# STM32L562 register map
File version: 1.1
Registers are 32-bit, read-write, reset 0x0 unless marked. A register's access mark holds for its fields unless they carry their own. Offsets are from the block's base; [hi:lo] are bit positions; {n}, {i} and the like mark numbered series; 'fields as' and 'values as' point back to an identical list.

## NVIC — Nested Vectored Interrupt Controller
Base 0xE000E100
{0x0+4i} ISER{i} (i=0..2) — Interrupt Set-Enable Register
  [31:0] SETENA
0x0C ISER3 — Interrupt Set-Enable Register
{0x80+4i} ICER{i} (i=0..2) — Interrupt Clear-Enable Register
  [31:0] CLRENA
0x8C ICER3 — Interrupt Clear-Enable Register
{0x100+4i} ISPR{i} (i=0..2) — Interrupt Set-Pending Register
  [31:0] SETPEND
0x10C ISPR3 — Interrupt Set-Pending Register
{0x180+4i} ICPR{i} (i=0..2) — Interrupt Clear-Pending Register
  [31:0] CLRPEND
0x18C ICPR3 — Interrupt Clear-Pending Register
{0x200+4i} IABR{i} ro (i=0..2) — Interrupt Active Bit Register
  [31:0] ACTIVE
0x20C IABR3 — Interrupt Active Bit Register
{0x280+4i} ITNS{i} (i=0..15)
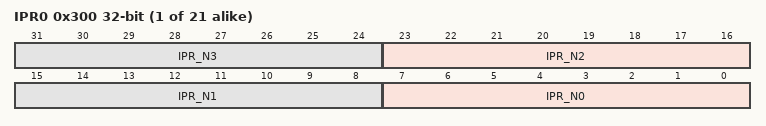
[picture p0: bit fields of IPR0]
{0x300+4i} IPR{i} (i=0..20) — Interrupt Priority Register
  [8n+7:8n] IPR_N{n} (n=0..3)
{0x300+4i} IPR{i} (i=21..29)

## NVIC_STIR — Nested vectored interrupt controller
Base 0xE000EF00
0x00 STIR — Software trigger interrupt register
  [8:0] INTID — Software generated interrupt ID

## RNG
Base 0x420C0800
Same registers: SEC_RNG 0x520C0800
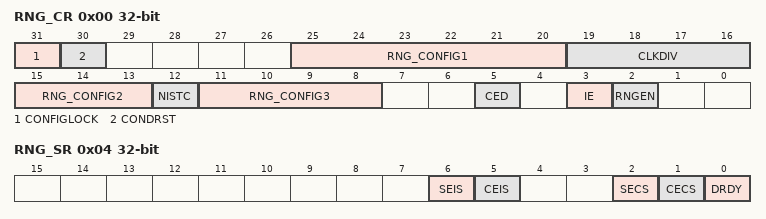
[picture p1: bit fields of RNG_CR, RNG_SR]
0x00 RNG_CR — RNG control register
  [31] CONFIGLOCK — RNG Config Lock
  [30] CONDRST — Conditioning soft reset
  [25:20] RNG_CONFIG1 — RNG configuration 1
  [19:16] CLKDIV — Clock divider factor
  [15:13] RNG_CONFIG2 — RNG configuration 2
  [12] NISTC — Non NIST compliant
  [11:8] RNG_CONFIG3 — RNG configuration 3
  [5] CED — Clock error detection Note: The clock error detection can be used only when ck_rc48 or ck_pll1_q (ck_pll1_q = 48MHz) source is selected otherwise, CED bit must be equal to 1. The clock error detection cannot be enabled nor disabled on the fly when RNG peripheral is enabled, to enable or disable CED the RNG must be disabled.
  [3] IE — Interrupt enable
  [2] RNGEN — Random number generator enable
0x04 RNG_SR access per field — RNG status register
  [6] SEIS rw — Seed error interrupt status This bit is set at the same time as SECS. It is cleared by writing it to 0. ** More than 64 consecutive bits at the same value (0 or 1) ** More than 32 consecutive alternances of 0 and 1 (0101010101...01) An interrupt is pending if IE = 1 in the RNG_CR register.
  [5] CEIS rw — Clock error interrupt status This bit is set at the same time as CECS. It is cleared by writing it to 0. An interrupt is pending if IE = 1 in the RNG_CR register. Note: This bit is meaningless if CED (Clock error detection) bit in RNG_CR is equal to 1.
  [2] SECS ro — Seed error current status ** More than 64 consecutive bits at the same value (0 or 1) ** More than 32 consecutive alternances of 0 and 1 (0101010101...01)
  [1] CECS ro — Clock error current status Note: This bit is meaningless if CED (Clock error detection) bit in RNG_CR is equal to 1.
  [0] DRDY ro — Data ready Note: If IE=1 in RNG_CR, an interrupt is generated when DRDY=1. It can rise when the peripheral is disabled. When the output buffer becomes empty (after reading RNG_DR), this bit returns to 0 until a new random value is generated.
0x08 RNG_DR ro — The RNG_DR register is a read-only register that delivers a 32-bit random value when read. The content of this register is valid when DRDY= 1, even if RNGEN=0.
  [31:0] RNDATA — Random data 32-bit random data which are valid when DRDY=1.
0x10 RNG_HTCR reset 0xCAA74 — The RNG_DR register is a read-only register that delivers a 32-bit random value when read. The content of this register is valid when DRDY= 1, even if RNGEN=0.
  [31:0] HTCFG — health test configuration

## DCB — Debug Control Block
Base 0xE000EE08
0x00 DSCSR — Debug Security Control and Status Register
  [16] CDS — Current domain Secure

## SAU — Security Attribution Unit
Base 0xE000EDD0
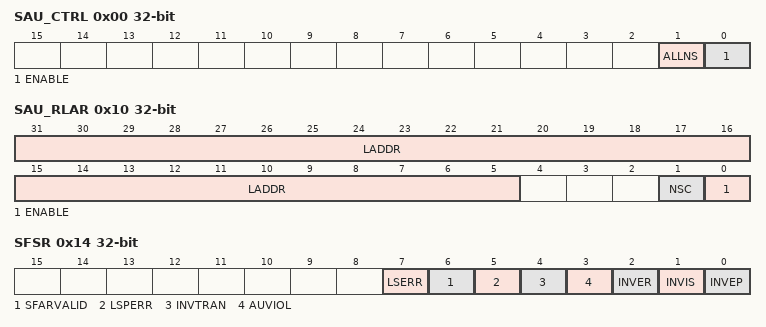
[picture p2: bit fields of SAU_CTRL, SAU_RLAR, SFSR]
0x00 SAU_CTRL — SAU Control Register
  [1] ALLNS — All Non-secure. When SAU_CTRL.ENABLE is 0 this bit controls if the memory is marked as Non-secure or Secure
  [0] ENABLE — Enables the SAU
0x04 SAU_TYPE reset 0x8 — Indicates the number of regions implemented by the Security Attribution Unit.
  [7:0] SREGION — The number of implemented SAU regions
0x08 SAU_RNR — Selects the region currently accessed by SAU_RBAR and SAU_RLAR
  [7:0] REGION — Indicates the SAU region accessed by SAU_RBAR and SAU_RLAR
0x0C SAU_RBAR — SAU Region Base Address Register
  [31:5] BADDR — Holds bits [31:5] of the base address for the selected SAU region
0x10 SAU_RLAR — SAU Region Limit Address Register
  [31:5] LADDR — Holds bits [31:5] of the limit address for the selected SAU region
  [1] NSC — Controls whether Non-secure state is permitted to execute an SG instruction from this region
  [0] ENABLE — SAU region enable
0x14 SFSR — Provides information about any security related faults
  [7] LSERR — Sticky flag indicating that an error occurred during lazy state activation or deactivation
  [6] SFARVALID — This bit is set when the SFAR register contains a valid value
  [5] LSPERR — Sticky flag indicating that an SAU or IDAU violation occurred during the lazy preservation of Floating-point state
  [4] INVTRAN — Sticky flag indicating that an exception was raised due to a branch that was not flagged as being domain crossing causing a transition from Secure to Non-secure memory
  [3] AUVIOL — Sticky flag indicating that an attempt was made to access parts of the address space that are marked as Secure with NS-Req for the transaction set to Non-secure
  [2] INVER — This can be caused by EXC_RETURN.DCRS being set to 0 when returning from an exception in the Non-secure state, or by EXC_RETURN.ES being set to 1 when returning from an exception in the Non-secure state
  [1] INVIS — This bit is set if the integrity signature in an exception stack frame is found to be invalid during the unstacking operation
  [0] INVEP — This bit is set if a function call from the Non-secure state or exception targets a non-SG instruction in the Secure state. This bit is also set if the target address is an SG instruction, but there is no matching SAU/IDAU region with the NSC flag set.
0x18 SFAR — Shows the address of the memory location that caused a Security violation
  [31:0] ADDRESS — The address of an access that caused an attribution unit violation

## MPU — Memory Protection Unit
Base 0xE000ED90
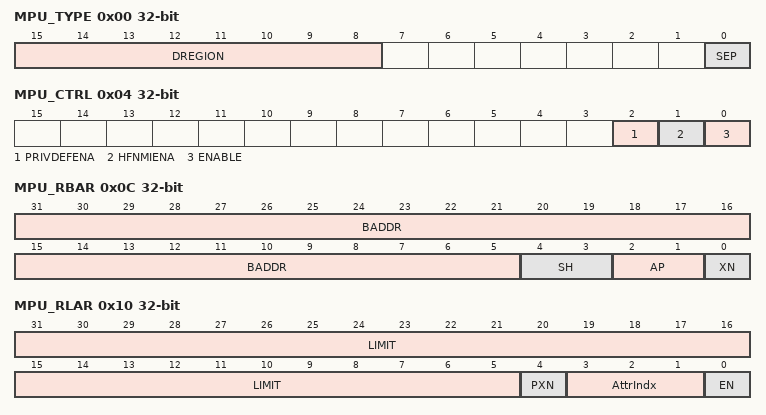
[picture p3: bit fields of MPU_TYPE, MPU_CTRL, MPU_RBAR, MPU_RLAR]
0x00 MPU_TYPE
  [15:8] DREGION — Data Regions
  [0] SEP — Separate instr/data
0x04 MPU_CTRL
  [2] PRIVDEFENA, [1] HFNMIENA, [0] ENABLE
0x08 MPU_RNR — Region select
  [7:0] REGION
0x0C MPU_RBAR — MPU Region Base Address Register
  [31:5] BADDR — Holds bits [31:5] of the base address for the selected MPU region
  [4:3] SH
  [2:1] AP
  [0] XN
0x10 MPU_RLAR
  [31:5] LIMIT — Holds bits [31:5] of the limit for the selected MPU region
  [4] PXN
  [3:1] AttrIndx
  [0] EN
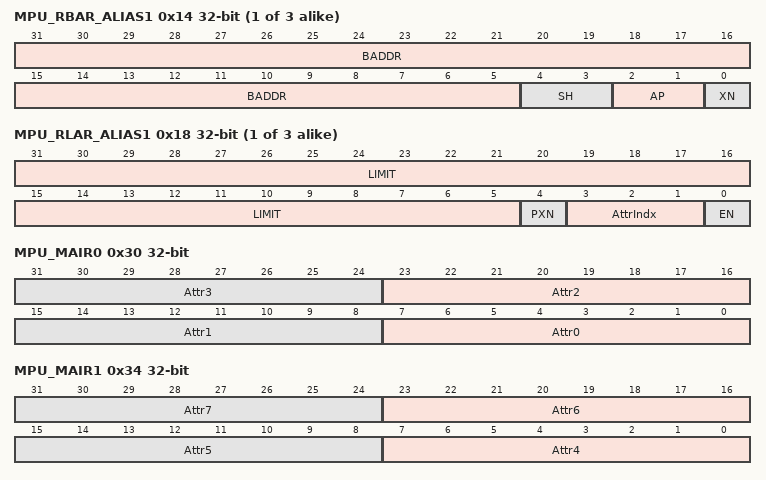
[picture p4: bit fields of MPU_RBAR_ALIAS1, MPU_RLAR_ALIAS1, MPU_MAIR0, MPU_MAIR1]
{0xC+8i} MPU_RBAR_ALIAS{i} (i=1..3)
  fields as MPU_RBAR
{0x10+8i} MPU_RLAR_ALIAS{i} (i=1..3)
  fields as MPU_RLAR
0x30 MPU_MAIR0
  [8n+7:8n] Attr{n} (n=0..3)
0x34 MPU_MAIR1
  [8n-25:8n-32] Attr{n} (n=4..7)

## HASH
Base 0x420C0400
Same registers: SEC_HASH 0x520C0400
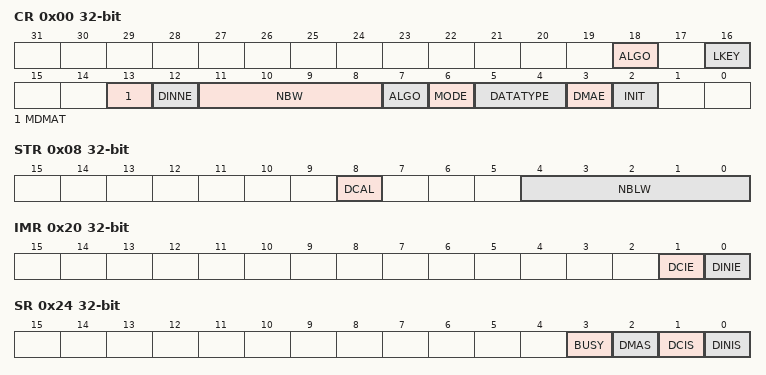
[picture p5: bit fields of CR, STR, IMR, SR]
0x00 CR
  [18] ALGO, [16] LKEY, [13] MDMAT, [12] DINNE, [11:8] NBW, [7] ALGO, [6] MODE, [5:4] DATATYPE, [3] DMAE, [2] INIT
0x04 DIN
  [31:0] DATAIN
0x08 STR
  [8] DCAL, [4:0] NBLW
{0xC+4i} HRA{i} (i=0..4)
  [31:0] H{i}
0x20 IMR
  [1] DCIE, [0] DINIE
0x24 SR
  [3] BUSY, [2] DMAS, [1] DCIS, [0] DINIS
{0xF8+4i} CSR{i} (i=0..53)
{0x310+4i} HR{i} (i=0..7)
  [31:0] H{i}
